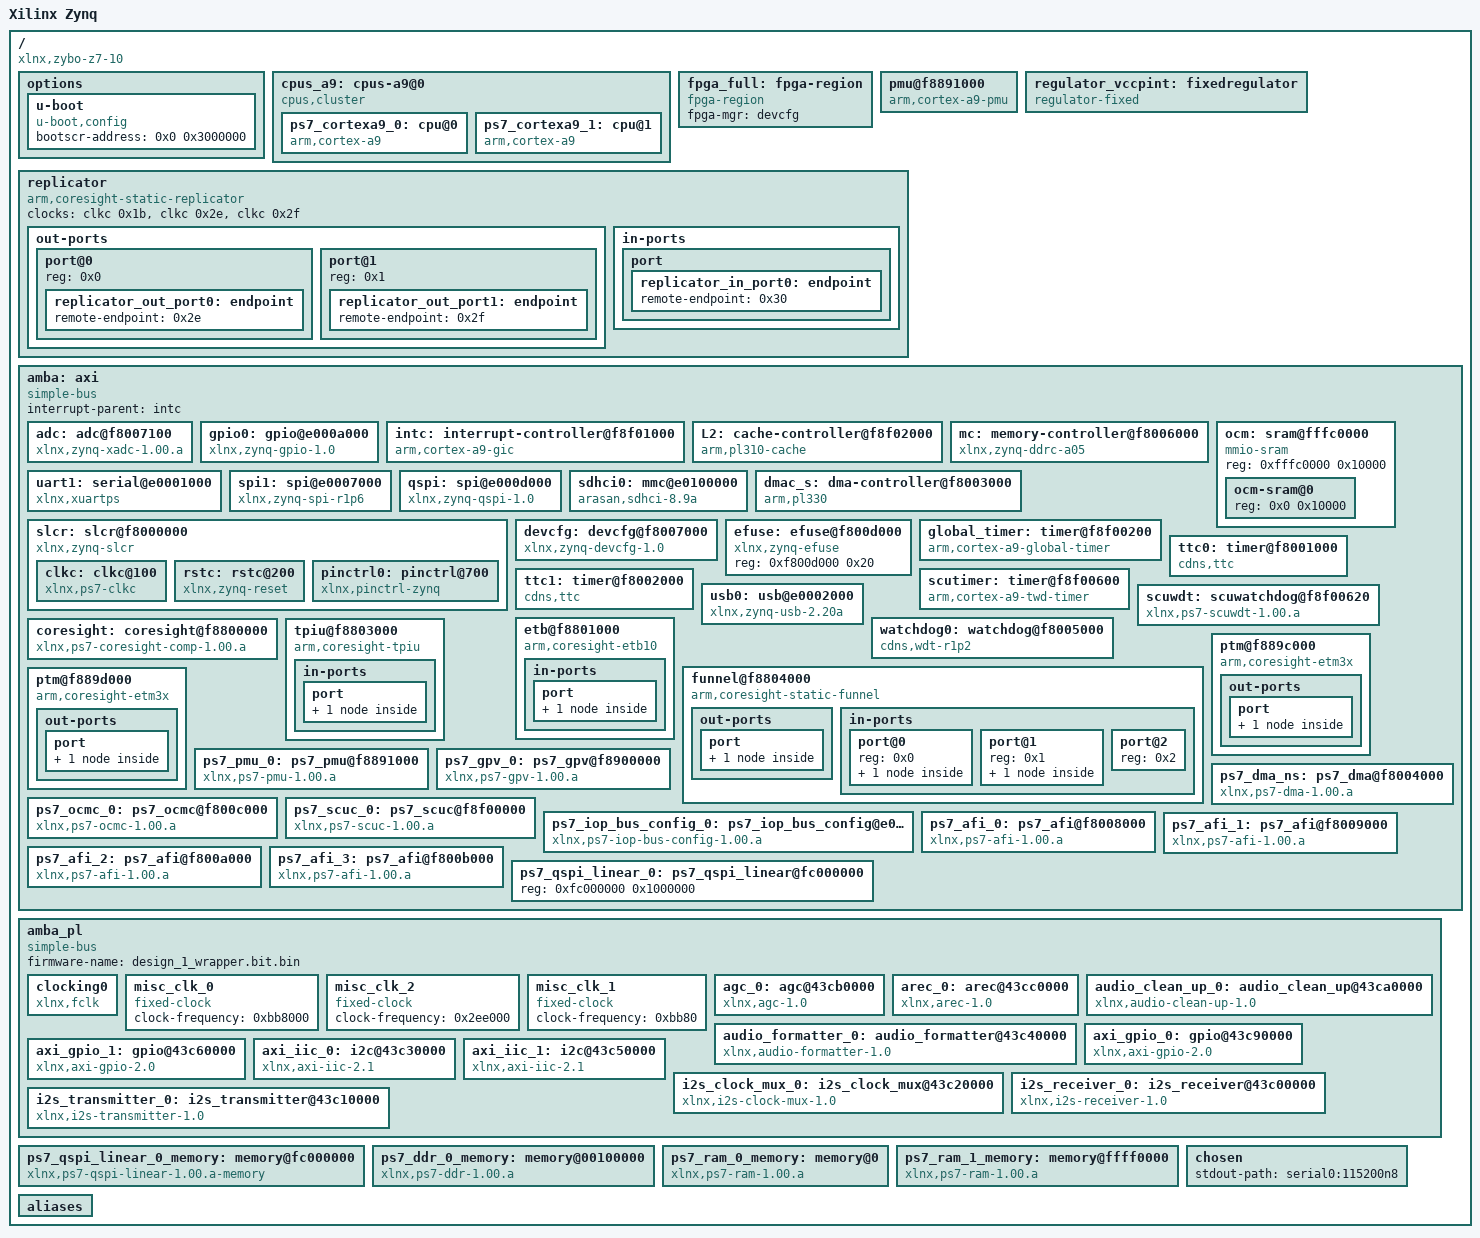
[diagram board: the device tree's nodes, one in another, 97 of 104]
/*
 * Xilinx Zynq 7000 DTSI
 * Describes the hardware common to all Zynq 7000-based boards.
 *
 *  Copyright (C) 2011 - 2015 Xilinx
 * (C) Copyright 2022-2024 Advanced Micro Devices, Inc. All Rights Reserved.
 */

/dts-v1/;

/ {
        #address-cells = <0x1>;
        #size-cells = <0x1>;
        compatible = "xlnx,zybo-z7-10";
        model = "Xilinx Zynq";
        board = "zybo-z7-10";
        device_id = "7z010";
        slrcount = <0x1>;
        family = "Zynq";
        pruned-sdt = <0x1>;

        options {

                u-boot {
                        compatible = "u-boot,config";
                        bootscr-address = <0x0 0x3000000>;
                };
        };

        cpus_a9: cpus-a9@0 {
                #address-cells = <0x1>;
                #size-cells = <0x0>;
                compatible = "cpus,cluster";
                address-map = <0xf0000000 &amba 0xf0000000 0x10000000>,
                 <0x100000 &ps7_ddr_0_memory 0x100000 0x3ff00000>,
                 <0x0 &ps7_ram_0_memory 0x0 0x30000>,
                 <0xffff0000 &ps7_ram_1_memory 0xffff0000 0xfe00>,
                 <0x43c00000 &i2s_receiver_0 0x43c00000 0x10000>,
                 <0x43c10000 &i2s_transmitter_0 0x43c10000 0x10000>,
                 <0x43c20000 &i2s_clock_mux_0 0x43c20000 0x10000>,
                 <0x43c30000 &axi_iic_0 0x43c30000 0x10000>,
                 <0x43c40000 &audio_formatter_0 0x43c40000 0x10000>,
                 <0x43c50000 &axi_iic_1 0x43c50000 0x10000>,
                 <0x43c60000 &axi_gpio_1 0x43c60000 0x10000>,
                 <0x43c90000 &axi_gpio_0 0x43c90000 0x10000>,
                 <0x43ca0000 &audio_clean_up_0 0x43ca0000 0x10000>,
                 <0x43cb0000 &agc_0 0x43cb0000 0x10000>,
                 <0x43cc0000 &arec_0 0x43cc0000 0x10000>,
                 <0xf8008000 &ps7_afi_0 0xf8008000 0x1000>,
                 <0xf8009000 &ps7_afi_1 0xf8009000 0x1000>,
                 <0xf800a000 &ps7_afi_2 0xf800a000 0x1000>,
                 <0xf800b000 &ps7_afi_3 0xf800b000 0x1000>,
                 <0xf8800000 &coresight 0xf8800000 0x100000>,
                 <0xf8006000 &mc 0xf8006000 0x1000>,
                 <0xf8007000 &devcfg 0xf8007000 0x100>,
                 <0xf8004000 &ps7_dma_ns 0xf8004000 0x1000>,
                 <0xf8003000 &dmac_s 0xf8003000 0x1000>,
                 <0xf8f00200 &global_timer 0xf8f00200 0x100>,
                 <0xe000a000 &gpio0 0xe000a000 0x1000>,
                 <0xf8900000 &ps7_gpv_0 0xf8900000 0x100000>,
                 <0xf8f01000 &intc 0xf8f01000 0x1000>,
                 <0xe0200000 &ps7_iop_bus_config_0 0xe0200000 0x1000>,
                 <0xf8f02000 &L2 0xf8f02000 0x1000>,
                 <0xf800c000 &ps7_ocmc_0 0xf800c000 0x1000>,
                 <0xf8891000 &ps7_pmu_0 0xf8891000 0x1000>,
                 <0xe000d000 &qspi 0xe000d000 0x1000>,
                 <0xfc000000 &ps7_qspi_linear_0_memory 0xfc000000 0x1000000>,
                 <0xf8f00000 &ps7_scuc_0 0xf8f00000 0xfd>,
                 <0xf8f00600 &scutimer 0xf8f00600 0x20>,
                 <0xf8f00620 &scuwdt 0xf8f00620 0xe0>,
                 <0xe0100000 &sdhci0 0xe0100000 0x1000>,
                 <0xf8000000 &slcr 0xf8000000 0x1000>,
                 <0xe0007000 &spi1 0xe0007000 0x1000>,
                 <0xe0001000 &uart1 0xe0001000 0x1000>,
                 <0xe0002000 &usb0 0xe0002000 0x1000>,
                 <0xf8007100 &adc 0xf8007100 0x21>;
                #ranges-address-cells = <0x1>;
                #ranges-size-cells = <0x1>;
                phandle = <0x3d>;

                ps7_cortexa9_0: cpu@0 {
                        compatible = "arm,cortex-a9";
                        device_type = "cpu";
                        reg = <0x0>;
                        clocks = <&clkc 0x3>;
                        clock-latency = <0x3e8>;
                        cpu0-supply = <0x2d>;
                        operating-points = <0xa2c2b 0xf4240 0x51616 0xf4240>;
                        xlnx,rable = <0x0>;
                        xlnx,i-cache-size = <0x8000>;
                        xlnx,d-cache-line-size = <0x14>;
                        xlnx,i-cache-line-size = <0x14>;
                        xlnx,cpu-1x-clk-freq-hz = <0x69f6bcb>;
                        xlnx,ip-name = "ps7_cortexa9";
                        xlnx,d-cache-size = <0x8000>;
                        xlnx,num-cores = <0x2>;
                        xlnx,cpu-clk-freq-hz = <0x27bc86bf>;
                        bus-handle = <0x1>;
                        phandle = <0x36>;
                };

                ps7_cortexa9_1: cpu@1 {
                        compatible = "arm,cortex-a9";
                        device_type = "cpu";
                        reg = <0x1>;
                        clocks = <&clkc 0x3>;
                        xlnx,rable = <0x0>;
                        xlnx,i-cache-size = <0x8000>;
                        xlnx,d-cache-line-size = <0x14>;
                        xlnx,i-cache-line-size = <0x14>;
                        xlnx,cpu-1x-clk-freq-hz = <0x69f6bcb>;
                        xlnx,ip-name = "ps7_cortexa9";
                        xlnx,d-cache-size = <0x8000>;
                        xlnx,cpu-clk-freq-hz = <0x27bc86bf>;
                        bus-handle = <0x1>;
                        phandle = <0x38>;
                };
        };

        fpga_full: fpga-region {
                compatible = "fpga-region";
                fpga-mgr = <&devcfg>;
                #address-cells = <0x1>;
                #size-cells = <0x1>;
                ranges;
                phandle = <0x3e>;
        };

        pmu@f8891000 {
                compatible = "arm,cortex-a9-pmu";
                interrupts = <0x0 0x5 0x4 0x0 0x6 0x4>;
                interrupt-parent = <&intc>;
                reg = <0xf8891000 0x1000 0xf8893000 0x1000>;
        };

        regulator_vccpint: fixedregulator {
                compatible = "regulator-fixed";
                regulator-name = "VCCPINT";
                regulator-min-microvolt = <0xf4240>;
                regulator-max-microvolt = <0xf4240>;
                regulator-boot-on;
                regulator-always-on;
                phandle = <0x2d>;
        };

        replicator {
                compatible = "arm,coresight-static-replicator";
                clocks = <&clkc 0x1b>,
                 <&clkc 0x2e>,
                 <&clkc 0x2f>;
                clock-names = "apb_pclk", "dbg_trc", "dbg_apb";

                out-ports {
                        #address-cells = <0x1>;
                        #size-cells = <0x0>;
                        /* replicator output ports */

                        port@0 {
                                reg = <0x0>;

                                replicator_out_port0: endpoint {
                                        remote-endpoint = <0x2e>;
                                        phandle = <0x32>;
                                };
                        };

                        port@1 {
                                reg = <0x1>;

                                replicator_out_port1: endpoint {
                                        remote-endpoint = <0x2f>;
                                        phandle = <0x31>;
                                };
                        };
                };

                in-ports {
                        /* replicator input port */

                        port {

                                replicator_in_port0: endpoint {
                                        remote-endpoint = <0x30>;
                                        phandle = <0x33>;
                                };
                        };
                };
        };

        amba: axi {
                bootph-all;
                compatible = "simple-bus";
                #address-cells = <0x1>;
                #size-cells = <0x1>;
                interrupt-parent = <&intc>;
                ranges;
                phandle = <0x1>;

                adc: adc@f8007100 {
                        compatible = "xlnx,zynq-xadc-1.00.a";
                        reg = <0xf8007100 0x20>;
                        interrupts = <0x0 0x7 0x4>;
                        interrupt-parent = <&intc>;
                        clocks = <&clkc 0xc>;
                        xlnx,rable = <0x0>;
                        status = "okay";
                        xlnx,ip-name = "ps7_xadc";
                        xlnx,name = "ps7_xadc_0";
                        phandle = <0x2b>;
                };

                gpio0: gpio@e000a000 {
                        compatible = "xlnx,zynq-gpio-1.0";
                        #gpio-cells = <0x2>;
                        clocks = <&clkc 0x2a>;
                        gpio-controller;
                        interrupt-controller;
                        #interrupt-cells = <0x2>;
                        interrupt-parent = <&intc>;
                        interrupts = <0x0 0x14 0x4>;
                        reg = <0xe000a000 0x1000>;
                        xlnx,rable = <0x0>;
                        xlnx,mio-gpio-mask = <0x5600>;
                        status = "okay";
                        gpio-mask-high = <0x0>;
                        xlnx,emio-gpio-width = <0x2>;
                        xlnx,ip-name = "ps7_gpio";
                        gpio-mask-low = <0x5600>;
                        emio-gpio-width = <0x2>;
                        xlnx,name = "ps7_gpio_0";
                        phandle = <0x1a>;
                };

                intc: interrupt-controller@f8f01000 {
                        compatible = "arm,cortex-a9-gic";
                        #interrupt-cells = <0x3>;
                        interrupt-controller;
                        reg = <0xf8f01000 0x1000 0xf8f00100 0x100>;
                        xlnx,rable = <0x0>;
                        status = "okay";
                        xlnx,irq-f2p-mode = "DIRECT";
                        xlnx,ip-name = "ps7_intc_dist";
                        xlnx,name = "ps7_intc_dist_0";
                        phandle = <0x1c>;
                };

                L2: cache-controller@f8f02000 {
                        compatible = "arm,pl310-cache";
                        reg = <0xf8f02000 0x1000>;
                        interrupts = <0x0 0x2 0x4>;
                        arm,data-latency = <0x3 0x2 0x2>;
                        arm,tag-latency = <0x2 0x2 0x2>;
                        cache-unified;
                        cache-level = <0x2>;
                        xlnx,rable = <0x0>;
                        status = "okay";
                        xlnx,ip-name = "ps7_pl310";
                        xlnx,name = "ps7_pl310_0";
                        phandle = <0x1e>;
                };

                mc: memory-controller@f8006000 {
                        compatible = "xlnx,zynq-ddrc-a05";
                        reg = <0xf8006000 0x1000>;
                        xlnx,rable = <0x0>;
                        status = "okay";
                        xlnx,ddr-clk-freq-hz = <0x1fca057e>;
                        xlnx,ip-name = "ps7_ddrc";
                        xlnx,has-ecc = <0x0>;
                        xlnx,name = "ps7_ddrc_0";
                        phandle = <0x15>;
                };

                ocm: sram@fffc0000 {
                        compatible = "mmio-sram";
                        reg = <0xfffc0000 0x10000>;
                        #address-cells = <0x1>;
                        #size-cells = <0x1>;
                        ranges = <0x0 0xfffc0000 0x10000>;
                        phandle = <0x43>;

                        ocm-sram@0 {
                                reg = <0x0 0x10000>;
                        };
                };

                uart1: serial@e0001000 {
                        compatible = "xlnx,xuartps", "cdns,uart-r1p8";
                        status = "okay";
                        clocks = <&clkc 0x18>,
                         <&clkc 0x29>;
                        clock-names = "uart_clk", "pclk";
                        reg = <0xe0001000 0x1000>;
                        interrupts = <0x0 0x32 0x4>;
                        interrupt-parent = <&intc>;
                        xlnx,rable = <0x0>;
                        xlnx,clock-freq = <0x5f5e100>;
                        xlnx,has-modem = <0x0>;
                        xlnx,ip-name = "ps7_uart";
                        cts-override;
                        port-number = <0x0>;
                        xlnx,uart-clk-freq-hz = <0x5f5e100>;
                        xlnx,name = "ps7_uart_1";
                        phandle = <0x29>;
                };

                spi1: spi@e0007000 {
                        compatible = "xlnx,zynq-spi-r1p6";
                        reg = <0xe0007000 0x1000>;
                        status = "okay";
                        interrupt-parent = <&intc>;
                        interrupts = <0x0 0x31 0x4>;
                        clocks = <&clkc 0x1a>,
                         <&clkc 0x23>;
                        clock-names = "ref_clk", "pclk";
                        #address-cells = <0x1>;
                        #size-cells = <0x0>;
                        xlnx,rable = <0x0>;
                        xlnx,has-ss0 = <0x1>;
                        xlnx,ip-name = "ps7_spi";
                        xlnx,has-ss1 = <0x1>;
                        num-cs = <0x2>;
                        xlnx,spi-clk-freq-hz = <0x9ef21b0>;
                        xlnx,has-ss2 = <0x0>;
                        xlnx,name = "ps7_spi_1";
                        phandle = <0x28>;
                };

                qspi: spi@e000d000 {
                        compatible = "xlnx,zynq-qspi-1.0";
                        reg = <0xe000d000 0x1000>;
                        interrupt-parent = <&intc>;
                        interrupts = <0x0 0x13 0x4>;
                        clocks = <&clkc 0xa>,
                         <&clkc 0x2b>;
                        clock-names = "ref_clk", "pclk";
                        status = "okay";
                        #address-cells = <0x1>;
                        #size-cells = <0x0>;
                        num-cs = <0x1>;
                        xlnx,qspi-clk-freq-hz = <0xbebc200>;
                        xlnx,rable = <0x0>;
                        xlnx,bus-width = <0x2>;
                        xlnx,ip-name = "ps7_qspi";
                        spi-rx-bus-width = <0x4>;
                        xlnx,connection-mode = <0x0>;
                        spi-tx-bus-width = <0x4>;
                        qspi-fbclk = <0x0>;
                        xlnx,clock-freq = <0xbebc200>;
                        xlnx,fb-clk = <0x1>;
                        xlnx,qspi-mode = <0x0>;
                        xlnx,name = "ps7_qspi_0";
                        xlnx,qspi-bus-width = <0x2>;
                        is-dual = <0x0>;
                        phandle = <0x21>;
                };

                sdhci0: mmc@e0100000 {
                        compatible = "arasan,sdhci-8.9a";
                        status = "okay";
                        clock-names = "clk_xin", "clk_ahb";
                        clocks = <&clkc 0x15>,
                         <&clkc 0x20>;
                        interrupt-parent = <&intc>;
                        interrupts = <0x0 0x18 0x4>;
                        reg = <0xe0100000 0x1000>;
                        xlnx,rable = <0x0>;
                        xlnx,has-power = <0x0>;
                        xlnx,ip-name = "ps7_sdio";
                        xlnx,sdio-clk-freq-hz = <0x2faf080>;
                        xlnx,has-wp = <0x0>;
                        xlnx,has-cd = <0x1>;
                        xlnx,name = "ps7_sd_0";
                        phandle = <0x26>;
                };

                slcr: slcr@f8000000 {
                        bootph-all;
                        #address-cells = <0x1>;
                        #size-cells = <0x1>;
                        compatible = "xlnx,zynq-slcr", "syscon", "simple-mfd";
                        reg = <0xf8000000 0x1000>;
                        ranges;
                        xlnx,rable = <0x0>;
                        status = "okay";
                        xlnx,ip-name = "ps7_slcr";
                        xlnx,name = "ps7_slcr_0";
                        phandle = <0x27>;

                        clkc: clkc@100 {
                                bootph-all;
                                #clock-cells = <0x1>;
                                compatible = "xlnx,ps7-clkc";
                                fclk-enable = <0x1>;
                                clock-output-names = "armpll", "ddrpll", "iopll", "cpu_6or4x", "cpu_3or2x", "cpu_2x", "cpu_1x", "ddr2x", "ddr3x", "dci", "lqspi", "smc", "pcap", "gem0", "gem1", "fclk0", "fclk1", "fclk2", "fclk3", "can0", "can1", "sdio0", "sdio1", "uart0", "uart1", "spi0", "spi1", "dma", "usb0_aper", "usb1_aper", "gem0_aper", "gem1_aper", "sdio0_aper", "sdio1_aper", "spi0_aper", "spi1_aper", "can0_aper", "can1_aper", "i2c0_aper", "i2c1_aper", "uart0_aper", "uart1_aper", "gpio_aper", "lqspi_aper", "smc_aper", "swdt", "dbg_trc", "dbg_apb";
                                reg = <0x100 0x100>;
                                ps-clk-frequency = <0x1fca055>;
                                phandle = <0x2c>;
                        };

                        rstc: rstc@200 {
                                compatible = "xlnx,zynq-reset";
                                reg = <0x200 0x48>;
                                #reset-cells = <0x1>;
                                syscon = <0x27>;
                                phandle = <0x4c>;
                        };

                        pinctrl0: pinctrl@700 {
                                compatible = "xlnx,pinctrl-zynq";
                                reg = <0x700 0x200>;
                                syscon = <0x27>;
                                phandle = <0x4d>;
                        };
                };

                dmac_s: dma-controller@f8003000 {
                        compatible = "arm,pl330", "arm,primecell";
                        reg = <0xf8003000 0x1000>;
                        interrupt-parent = <&intc>;
                        /*
                         * interrupt-names = "abort", "dma0", "dma1", "dma2", "dma3",
                         * "dma4", "dma5", "dma6", "dma7";
                         */
                        interrupts = <0x0 0xd 0x4 0x0 0xe 0x4 0x0 0xf 0x4 0x0 0x10 0x4 0x0 0x11 0x4 0x0 0x28 0x4 0x0 0x29 0x4 0x0 0x2a 0x4 0x0 0x2b 0x4>;
                        #dma-cells = <0x1>;
                        clocks = <&clkc 0x1b>;
                        clock-names = "apb_pclk";
                        xlnx,rable = <0x0>;
                        status = "okay";
                        xlnx,ip-name = "ps7_dma";
                        xlnx,is-secure;
                        xlnx,name = "ps7_dma_s";
                        phandle = <0x18>;
                };

                devcfg: devcfg@f8007000 {
                        compatible = "xlnx,zynq-devcfg-1.0";
                        reg = <0xf8007000 0x100>;
                        interrupt-parent = <&intc>;
                        interrupts = <0x0 0x8 0x4>;
                        clocks = <&clkc 0xc>,
                         <&clkc 0xf>,
                         <&clkc 0x10>,
                         <&clkc 0x11>,
                         <&clkc 0x12>;
                        clock-names = "ref_clk", "fclk0", "fclk1", "fclk2", "fclk3";
                        syscon = <0x27>;
                        xlnx,rable = <0x0>;
                        status = "okay";
                        xlnx,ip-name = "ps7_dev_cfg";
                        xlnx,name = "ps7_dev_cfg_0";
                        phandle = <0x16>;
                };

                efuse: efuse@f800d000 {
                        compatible = "xlnx,zynq-efuse";
                        reg = <0xf800d000 0x20>;
                        phandle = <0x4e>;
                };

                global_timer: timer@f8f00200 {
                        compatible = "arm,cortex-a9-global-timer";
                        reg = <0xf8f00200 0x20>;
                        interrupts = <0x1 0xb 0x301>;
                        interrupt-parent = <&intc>;
                        clocks = <&clkc 0x4>;
                        xlnx,rable = <0x0>;
                        status = "okay";
                        xlnx,ip-name = "ps7_globaltimer";
                        xlnx,name = "ps7_globaltimer_0";
                        phandle = <0x19>;
                };

                ttc0: timer@f8001000 {
                        interrupt-parent = <&intc>;
                        interrupts = <0x0 0xa 0x4 0x0 0xb 0x4 0x0 0xc 0x4>;
                        compatible = "cdns,ttc";
                        clocks = <&clkc 0x6>;
                        reg = <0xf8001000 0x1000>;
                        phandle = <0x4f>;
                };

                ttc1: timer@f8002000 {
                        interrupt-parent = <&intc>;
                        interrupts = <0x0 0x25 0x4 0x0 0x26 0x4 0x0 0x27 0x4>;
                        compatible = "cdns,ttc";
                        clocks = <&clkc 0x6>;
                        reg = <0xf8002000 0x1000>;
                        phandle = <0x50>;
                };

                scutimer: timer@f8f00600 {
                        bootph-all;
                        interrupt-parent = <&intc>;
                        interrupts = <0x1 0xd 0x301>;
                        compatible = "arm,cortex-a9-twd-timer";
                        reg = <0xf8f00600 0x20>;
                        clocks = <&clkc 0x4>;
                        xlnx,rable = <0x0>;
                        status = "okay";
                        xlnx,ip-name = "ps7_scutimer";
                        xlnx,name = "ps7_scutimer_0";
                        phandle = <0x24>;
                };

                scuwdt: scuwatchdog@f8f00620 {
                        interrupt-parent = <&intc>;
                        interrupts = <0x1 0xe 0x4>;
                        compatible = "xlnx,ps7-scuwdt-1.00.a";
                        reg = <0xf8f00620 0xe0>;
                        xlnx,rable = <0x0>;
                        status = "okay";
                        xlnx,ip-name = "ps7_scuwdt";
                        xlnx,name = "ps7_scuwdt_0";
                        phandle = <0x25>;
                };

                usb0: usb@e0002000 {
                        compatible = "xlnx,zynq-usb-2.20a", "chipidea,usb2";
                        status = "okay";
                        clocks = <&clkc 0x1c>;
                        interrupt-parent = <&intc>;
                        interrupts = <0x0 0x15 0x4>;
                        reg = <0xe0002000 0x1000>;
                        phy_type = "ulpi";
                        xlnx,rable = <0x0>;
                        xlnx,usb-reset = "MIO , 46";
                        xlnx,ip-name = "ps7_usb";
                        usb-reset = <0x1a 0x2e 0x0>;
                        xlnx,name = "ps7_usb_0";
                        phandle = <0x2a>;
                };

                watchdog0: watchdog@f8005000 {
                        clocks = <&clkc 0x2d>;
                        compatible = "cdns,wdt-r1p2";
                        interrupt-parent = <&intc>;
                        interrupts = <0x0 0x9 0x1>;
                        reg = <0xf8005000 0x1000>;
                        timeout-sec = <0xa>;
                        phandle = <0x52>;
                };

                coresight: coresight@f8800000 {
                        compatible = "xlnx,ps7-coresight-comp-1.00.a";
                        status = "okay";
                        reg = <0xf8800000 0x100000>;
                        xlnx,rable = <0x0>;
                        xlnx,ip-name = "ps7_coresight_comp";
                        xlnx,name = "ps7_coresight_comp_0";
                        phandle = <0x14>;
                };

                etb@f8801000 {
                        compatible = "arm,coresight-etb10", "arm,primecell";
                        reg = <0xf8801000 0x1000>;
                        clocks = <&clkc 0x1b>,
                         <&clkc 0x2e>,
                         <&clkc 0x2f>;
                        clock-names = "apb_pclk", "dbg_trc", "dbg_apb";

                        in-ports {

                                port {

                                        etb_in_port: endpoint {
                                                remote-endpoint = <0x31>;
                                                phandle = <0x2f>;
                                        };
                                };
                        };
                };

                tpiu@f8803000 {
                        compatible = "arm,coresight-tpiu", "arm,primecell";
                        reg = <0xf8803000 0x1000>;
                        clocks = <&clkc 0x1b>,
                         <&clkc 0x2e>,
                         <&clkc 0x2f>;
                        clock-names = "apb_pclk", "dbg_trc", "dbg_apb";

                        in-ports {

                                port {

                                        tpiu_in_port: endpoint {
                                                remote-endpoint = <0x32>;
                                                phandle = <0x2e>;
                                        };
                                };
                        };
                };

                funnel@f8804000 {
                        compatible = "arm,coresight-static-funnel", "arm,primecell";
                        reg = <0xf8804000 0x1000>;
                        clocks = <&clkc 0x1b>,
                         <&clkc 0x2e>,
                         <&clkc 0x2f>;
                        clock-names = "apb_pclk", "dbg_trc", "dbg_apb";
                        /* funnel output ports */

                        out-ports {

                                port {

                                        funnel_out_port: endpoint {
                                                remote-endpoint = <0x33>;
                                                phandle = <0x30>;
                                        };
                                };
                        };

                        in-ports {
                                #address-cells = <0x1>;
                                #size-cells = <0x0>;
                                /* funnel input ports */

                                port@0 {
                                        reg = <0x0>;

                                        funnel0_in_port0: endpoint {
                                                remote-endpoint = <0x34>;
                                                phandle = <0x37>;
                                        };
                                };

                                port@1 {
                                        reg = <0x1>;

                                        funnel0_in_port1: endpoint {
                                                remote-endpoint = <0x35>;
                                                phandle = <0x39>;
                                        };
                                };

                                port@2 {
                                        reg = <0x2>;
                                };
                        };
                };

                ptm@f889c000 {
                        compatible = "arm,coresight-etm3x", "arm,primecell";
                        reg = <0xf889c000 0x1000>;
                        clocks = <&clkc 0x1b>,
                         <&clkc 0x2e>,
                         <&clkc 0x2f>;
                        clock-names = "apb_pclk", "dbg_trc", "dbg_apb";
                        cpu = <0x36>;

                        out-ports {

                                port {

                                        ptm0_out_port: endpoint {
                                                remote-endpoint = <0x37>;
                                                phandle = <0x34>;
                                        };
                                };
                        };
                };

                ptm@f889d000 {
                        compatible = "arm,coresight-etm3x", "arm,primecell";
                        reg = <0xf889d000 0x1000>;
                        clocks = <&clkc 0x1b>,
                         <&clkc 0x2e>,
                         <&clkc 0x2f>;
                        clock-names = "apb_pclk", "dbg_trc", "dbg_apb";
                        cpu = <0x38>;

                        out-ports {

                                port {

                                        ptm1_out_port: endpoint {
                                                remote-endpoint = <0x39>;
                                                phandle = <0x35>;
                                        };
                                };
                        };
                };

                ps7_pmu_0: ps7_pmu@f8891000 {
                        xlnx,rable = <0x0>;
                        compatible = "xlnx,ps7-pmu-1.00.a";
                        status = "okay";
                        xlnx,ip-name = "ps7_pmu";
                        reg = <0xf8891000 0x1000 0xf8893000 0x1000>;
                        xlnx,name = "ps7_pmu_0";
                        phandle = <0x20>;
                };

                ps7_ocmc_0: ps7_ocmc@f800c000 {
                        xlnx,rable = <0x0>;
                        compatible = "xlnx,ps7-ocmc-1.00.a";
                        status = "okay";
                        xlnx,ip-name = "ps7_ocmc";
                        reg = <0xf800c000 0x1000>;
                        xlnx,name = "ps7_ocmc_0";
                        phandle = <0x1f>;
                };

                ps7_gpv_0: ps7_gpv@f8900000 {
                        xlnx,rable = <0x0>;
                        compatible = "xlnx,ps7-gpv-1.00.a";
                        status = "okay";
                        xlnx,ip-name = "ps7_gpv";
                        reg = <0xf8900000 0x100000>;
                        xlnx,name = "ps7_gpv_0";
                        phandle = <0x1b>;
                };

                ps7_scuc_0: ps7_scuc@f8f00000 {
                        xlnx,rable = <0x0>;
                        compatible = "xlnx,ps7-scuc-1.00.a";
                        status = "okay";
                        xlnx,ip-name = "ps7_scuc";
                        reg = <0xf8f00000 0xfd>;
                        xlnx,name = "ps7_scuc_0";
                        phandle = <0x23>;
                };

                ps7_iop_bus_config_0: ps7_iop_bus_config@e0200000 {
                        xlnx,rable = <0x0>;
                        compatible = "xlnx,ps7-iop-bus-config-1.00.a";
                        status = "okay";
                        xlnx,ip-name = "ps7_iop_bus_config";
                        reg = <0xe0200000 0x1000>;
                        xlnx,name = "ps7_iop_bus_config_0";
                        phandle = <0x1d>;
                };

                ps7_dma_ns: ps7_dma@f8004000 {
                        xlnx,rable = <0x0>;
                        compatible = "xlnx,ps7-dma-1.00.a";
                        status = "okay";
                        xlnx,ip-name = "ps7_dma";
                        xlnx,is-secure;
                        reg = <0xf8004000 0x1000>;
                        xlnx,name = "ps7_dma_ns";
                        phandle = <0x17>;
                };

                ps7_afi_0: ps7_afi@f8008000 {
                        xlnx,rable = <0x0>;
                        compatible = "xlnx,ps7-afi-1.00.a";
                        status = "okay";
                        xlnx,ip-name = "ps7_afi";
                        reg = <0xf8008000 0x1000>;
                        xlnx,name = "ps7_afi_0";
                        phandle = <0x10>;
                };

                ps7_afi_1: ps7_afi@f8009000 {
                        xlnx,rable = <0x0>;
                        compatible = "xlnx,ps7-afi-1.00.a";
                        status = "okay";
                        xlnx,ip-name = "ps7_afi";
                        reg = <0xf8009000 0x1000>;
                        xlnx,name = "ps7_afi_1";
                        phandle = <0x11>;
                };

                ps7_afi_2: ps7_afi@f800a000 {
                        xlnx,rable = <0x0>;
                        compatible = "xlnx,ps7-afi-1.00.a";
                        status = "okay";
                        xlnx,ip-name = "ps7_afi";
                        reg = <0xf800a000 0x1000>;
                        xlnx,name = "ps7_afi_2";
                        phandle = <0x12>;
                };

                ps7_afi_3: ps7_afi@f800b000 {
                        xlnx,rable = <0x0>;
                        compatible = "xlnx,ps7-afi-1.00.a";
                        status = "okay";
                        xlnx,ip-name = "ps7_afi";
                        reg = <0xf800b000 0x1000>;
                        xlnx,name = "ps7_afi_3";
                        phandle = <0x13>;
                };

                ps7_qspi_linear_0: ps7_qspi_linear@fc000000 {
                        reg = <0xfc000000 0x1000000>;
                        phandle = <0x58>;
                };
        };

        amba_pl: amba_pl {
                ranges;
                compatible = "simple-bus";
                #address-cells = <0x1>;
                #size-cells = <0x1>;
                firmware-name = "design_1_wrapper.bit.bin";
                phandle = <0x59>;

                clocking0: clocking0 {
                        compatible = "xlnx,fclk";
                        assigned-clocks = <&clkc 0xf>;
                        assigned-clock-rates = <0x5f5e100>;
                        #clock-cells = <0x0>;
                        clock-output-names = "fabric_clk";
                        clocks = <&clkc 0xf>;
                        phandle = <0x5a>;
                };

                misc_clk_0: misc_clk_0 {
                        compatible = "fixed-clock";
                        clock-frequency = <0xbb8000>;
                        #clock-cells = <0x0>;
                        phandle = <0x3a>;
                };

                misc_clk_2: misc_clk_2 {
                        compatible = "fixed-clock";
                        clock-frequency = <0x2ee000>;
                        #clock-cells = <0x0>;
                        phandle = <0x3c>;
                };

                misc_clk_1: misc_clk_1 {
                        compatible = "fixed-clock";
                        clock-frequency = <0xbb80>;
                        #clock-cells = <0x0>;
                        phandle = <0x3b>;
                };

                agc_0: agc@43cb0000 {
                        xlnx,rable = <0x0>;
                        xlnx,s00-axi-data-width = <0x20>;
                        compatible = "xlnx,agc-1.0";
                        status = "okay";
                        clock-names = "s00_axi_aclk";
                        xlnx,s00-axi-addr-width = <0x6>;
                        xlnx,ip-name = "agc";
                        xlnx,edk-iptype = "PERIPHERAL";
                        reg = <0x43cb0000 0x10000>;
                        clocks = <&clkc 0xf>;
                        xlnx,name = "agc_0";
                        phandle = <0xe>;
                };

                arec_0: arec@43cc0000 {
                        compatible = "xlnx,arec-1.0";
                        interrupts = <0x0 0x34 0x4>;
                        xlnx,s00-axi-data-width = <0x20>;
                        xlnx,rable = <0x0>;
                        interrupt-parent = <&intc>;
                        xlnx,ip-name = "arec";
                        reg = <0x43cc0000 0x10000>;
                        clocks = <&clkc 0xf>;
                        xlnx,edk-iptype = "PERIPHERAL";
                        status = "okay";
                        clock-names = "s00_axi_aclk";
                        xlnx,s00-axi-addr-width = <0x6>;
                        interrupt-names = "irq";
                        xlnx,name = "arec_0";
                        phandle = <0xf>;
                };

                audio_clean_up_0: audio_clean_up@43ca0000 {
                        compatible = "xlnx,audio-clean-up-1.0";
                        xlnx,ii = "52 , ~ , 74";
                        xlnx,machine = <0x40>;
                        xlnx,s-axi-acu-addr-width = <0x7>;
                        xlnx,rable = <0x0>;
                        xlnx,ip-name = "audio_clean_up";
                        reg = <0x43ca0000 0x10000>;
                        clocks = <&clkc 0xf>;
                        xlnx,clk-period = <0xa>;
                        xlnx,s-axi-acu-data-width = <0x20>;
                        xlnx,edk-iptype = "PERIPHERAL";
                        status = "okay";
                        clock-names = "ap_clk";
                        xlnx,combinational = <0x0>;
                        xlnx,latency = <0x33>;
                        xlnx,name = "audio_clean_up_0";
                        phandle = <0xd>;
                };

                audio_formatter_0: audio_formatter@43c40000 {
                        xlnx,rx = <0xd>;
                        interrupts = <0x0 0x1f 0x4 0x0 0x20 0x4>;
                        compatible = "xlnx,audio-formatter-1.0", "xlnx,audio-formatter-1.0";
                        xlnx,packing-mode-mm2s = <0x0>;
                        xlnx,mm2s-async-clock = <0x0>;
                        xlnx,tx = <0xe>;
                        xlnx,mm2s-addr-width = <0x20>;
                        interrupt-parent = <&intc>;
                        xlnx,rable = <0x0>;
                        xlnx,s2mm-dataformat = <0x1>;
                        xlnx,ip-name = "audio_formatter";
                        reg = <0x43c40000 0x10000>;
                        xlnx,include-s2mm = <0x1>;
                        xlnx,max-num-channels-mm2s = <0x2>;
                        clocks = <&misc_clk_0>,
                         <&clkc 0xf>,
                         <&clkc 0xf>,
                         <&clkc 0xf>;
                        xlnx,s2mm-async-clock = <0x0>;
                        xlnx,packing-mode-s2mm = <0x0>;
                        xlnx,edk-iptype = "PERIPHERAL";
                        xlnx,s2mm-addr-width = <0x20>;
                        status = "okay";
                        clock-names = "aud_mclk", "m_axis_mm2s_aclk", "s_axi_lite_aclk", "s_axis_s2mm_aclk";
                        xlnx,mm2s-dataformat = <0x3>;
                        interrupt-names = "irq_mm2s", "irq_s2mm";
                        xlnx,include-mm2s = <0x1>;
                        xlnx,max-num-channels-s2mm = <0x2>;
                        xlnx,name = "audio_formatter_0";
                        phandle = <0x9>;
                };

                axi_gpio_0: gpio@43c90000 {
                        #interrupt-cells = <0x2>;
                        interrupts = <0x0 0x22 0x4>;
                        xlnx,gpio-board-interface = "btns_4bits";
                        compatible = "xlnx,axi-gpio-2.0", "xlnx,xps-gpio-1.00.a";
                        xlnx,all-outputs = <0x0>;
                        #gpio-cells = <0x2>;
                        xlnx,gpio-width = <0x4>;
                        interrupt-parent = <&intc>;
                        xlnx,rable = <0x0>;
                        xlnx,dout-default = <0x0>;
                        xlnx,is-dual = <0x1>;
                        xlnx,ip-name = "axi_gpio";
                        xlnx,tri-default-2 = <0xffffffff>;
                        reg = <0x43c90000 0x10000>;
                        xlnx,all-inputs-2 = <0x0>;
                        clocks = <&clkc 0xf>;
                        xlnx,all-outputs-2 = <0x1>;
                        gpio-controller;
                        xlnx,interrupt-present = <0x1>;
                        xlnx,gpio2-board-interface = "leds_4bits";
                        xlnx,edk-iptype = "PERIPHERAL";
                        xlnx,dout-default-2 = <0x0>;
                        status = "okay";
                        xlnx,gpio2-width = <0x4>;
                        clock-names = "s_axi_aclk";
                        xlnx,use-board-flow;
                        interrupt-controller;
                        interrupt-names = "ip2intc_irpt";
                        xlnx,tri-default = <0xffffffff>;
                        xlnx,name = "axi_gpio_0";
                        xlnx,all-inputs = <0x1>;
                        phandle = <0xc>;
                };

                axi_gpio_1: gpio@43c60000 {
                        #interrupt-cells = <0x2>;
                        interrupts = <0x0 0x24 0x4>;
                        xlnx,gpio-board-interface = "Custom";
                        compatible = "xlnx,axi-gpio-2.0", "xlnx,xps-gpio-1.00.a";
                        xlnx,all-outputs = <0x0>;
                        #gpio-cells = <0x2>;
                        xlnx,gpio-width = <0x2>;
                        interrupt-parent = <&intc>;
                        xlnx,rable = <0x0>;
                        xlnx,dout-default = <0x0>;
                        xlnx,is-dual = <0x1>;
                        xlnx,ip-name = "axi_gpio";
                        xlnx,tri-default-2 = <0xffffffff>;
                        reg = <0x43c60000 0x10000>;
                        xlnx,all-inputs-2 = <0x0>;
                        clocks = <&clkc 0xf>;
                        xlnx,all-outputs-2 = <0x1>;
                        gpio-controller;
                        xlnx,interrupt-present = <0x1>;
                        xlnx,gpio2-board-interface = "Custom";
                        xlnx,edk-iptype = "PERIPHERAL";
                        xlnx,dout-default-2 = <0x0>;
                        status = "okay";
                        xlnx,gpio2-width = <0x2>;
                        clock-names = "s_axi_aclk";
                        interrupt-controller;
                        interrupt-names = "ip2intc_irpt";
                        xlnx,tri-default = <0xffffffff>;
                        xlnx,name = "axi_gpio_1";
                        xlnx,all-inputs = <0x1>;
                        phandle = <0xb>;
                };

                axi_iic_0: i2c@43c30000 {
                        interrupts = <0x0 0x21 0x4>;
                        xlnx,iic-freq-khz = <0x64>;
                        compatible = "xlnx,axi-iic-2.1", "xlnx,xps-iic-2.00.a";
                        xlnx,scl-inertial-delay = <0x0>;
                        interrupt-parent = <&intc>;
                        xlnx,rable = <0x0>;
                        xlnx,ip-name = "axi_iic";
                        xlnx,disable-setup-violation-check = <0x0>;
                        reg = <0x43c30000 0x10000>;
                        clocks = <&clkc 0xf>;
                        xlnx,gpo-width = <0x1>;
                        xlnx,edk-iptype = "PERIPHERAL";
                        xlnx,static-timing-reg-width = <0x0>;
                        xlnx,sda-level = <0x1>;
                        status = "okay";
                        clock-names = "s_axi_aclk";
                        xlnx,ten-bit-adr = <0x0>;
                        xlnx,default-value = <0x0>;
                        interrupt-names = "iic2intc_irpt";
                        xlnx,iic-board-interface = "Custom";
                        xlnx,timing-reg-width = <0x20>;
                        xlnx,iic-freq = <0x186a0>;
                        xlnx,smbus-pmbus-host = <0x0>;
                        xlnx,name = "axi_iic_0";
                        xlnx,axi-aclk-freq-mhz = <0x64>;
                        xlnx,sda-inertial-delay = <0x0>;
                        phandle = <0x8>;
                };

                axi_iic_1: i2c@43c50000 {
                        interrupts = <0x0 0x23 0x4>;
                        xlnx,iic-freq-khz = <0x64>;
                        compatible = "xlnx,axi-iic-2.1", "xlnx,xps-iic-2.00.a";
                        xlnx,scl-inertial-delay = <0x0>;
                        interrupt-parent = <&intc>;
                        xlnx,rable = <0x0>;
                        xlnx,ip-name = "axi_iic";
                        xlnx,disable-setup-violation-check = <0x0>;
                        reg = <0x43c50000 0x10000>;
                        clocks = <&clkc 0xf>;
                        xlnx,gpo-width = <0x1>;
                        xlnx,edk-iptype = "PERIPHERAL";
                        xlnx,static-timing-reg-width = <0x0>;
                        xlnx,sda-level = <0x1>;
                        status = "okay";
                        clock-names = "s_axi_aclk";
                        xlnx,ten-bit-adr = <0x0>;
                        xlnx,default-value = <0x0>;
                        interrupt-names = "iic2intc_irpt";
                        xlnx,iic-board-interface = "Custom";
                        xlnx,timing-reg-width = <0x20>;
                        xlnx,iic-freq = <0x186a0>;
                        xlnx,smbus-pmbus-host = <0x0>;
                        xlnx,name = "axi_iic_1";
                        xlnx,axi-aclk-freq-mhz = <0x64>;
                        xlnx,sda-inertial-delay = <0x0>;
                        phandle = <0xa>;
                };

                i2s_clock_mux_0: i2s_clock_mux@43c20000 {
                        xlnx,rable = <0x0>;
                        xlnx,s00-axi-data-width = <0x20>;
                        compatible = "xlnx,i2s-clock-mux-1.0";
                        status = "okay";
                        clock-names = "lrclk_rx", "lrclk_tx", "s00_axi_aclk", "sclk_rx", "sclk_tx";
                        xlnx,s00-axi-addr-width = <0x4>;
                        xlnx,ip-name = "i2s_clock_mux";
                        xlnx,edk-iptype = "PERIPHERAL";
                        reg = <0x43c20000 0x10000>;
                        clocks = <&misc_clk_1>,
                         <&misc_clk_1>,
                         <&clkc 0xf>,
                         <&misc_clk_2>,
                         <&misc_clk_2>;
                        xlnx,name = "i2s_clock_mux_0";
                        phandle = <0x7>;
                };

                i2s_receiver_0: i2s_receiver@43c00000 {
                        aud_mclk = <0xbb8000>;
                        interrupts = <0x0 0x1d 0x4>;
                        compatible = "xlnx,i2s-receiver-1.0", "xlnx,i2s-receiver-1.0";
                        xlnx,dwidth = <0x10>;
                        xlnx,depth = <0x400>;
                        interrupt-parent = <&intc>;
                        xlnx,rable = <0x0>;
                        xlnx,ip-name = "i2s_receiver";
                        reg = <0x43c00000 0x10000>;
                        clocks = <&misc_clk_0>,
                         <&clkc 0xf>,
                         <&clkc 0xf>;
                        xlnx,num-channels = <0x1>;
                        xlnx,i2srx-board-interface = "Custom";
                        xlnx,edk-iptype = "PERIPHERAL";
                        xlnx,is-master = <0x1>;
                        status = "okay";
                        clock-names = "aud_mclk", "m_axis_aud_aclk", "s_axi_ctrl_aclk";
                        xlnx,32bit-lr = <0x0>;
                        interrupt-names = "irq";
                        xlnx,name = "i2s_receiver_0";
                        phandle = <0x5>;
                };

                i2s_transmitter_0: i2s_transmitter@43c10000 {
                        aud_mclk = <0xbb8000>;
                        interrupts = <0x0 0x1e 0x4>;
                        compatible = "xlnx,i2s-transmitter-1.0", "xlnx,i2s-transmitter-1.0";
                        xlnx,dwidth = <0x10>;
                        xlnx,depth = <0x80>;
                        interrupt-parent = <&intc>;
                        xlnx,rable = <0x0>;
                        xlnx,ip-name = "i2s_transmitter";
                        reg = <0x43c10000 0x10000>;
                        clocks = <&misc_clk_0>,
                         <&clkc 0xf>,
                         <&clkc 0xf>;
                        xlnx,num-channels = <0x1>;
                        xlnx,edk-iptype = "PERIPHERAL";
                        xlnx,is-master = <0x1>;
                        xlnx,i2stx-board-interface = "Custom";
                        status = "okay";
                        clock-names = "aud_mclk", "s_axi_ctrl_aclk", "s_axis_aud_aclk";
                        xlnx,32bit-lr = <0x0>;
                        interrupt-names = "irq";
                        xlnx,name = "i2s_transmitter_0";
                        phandle = <0x6>;
                };
        };

        ps7_qspi_linear_0_memory: memory@fc000000 {
                compatible = "xlnx,ps7-qspi-linear-1.00.a-memory";
                xlnx,ip-name = "ps7_qspi_linear";
                device_type = "memory";
                memory_type = "linear_flash";
                reg = <0xfc000000 0x1000000>;
                phandle = <0x22>;
        };

        ps7_ddr_0_memory: memory@00100000 {
                compatible = "xlnx,ps7-ddr-1.00.a";
                xlnx,ip-name = "ps7_ddr";
                device_type = "memory";
                memory_type = "memory";
                reg = <0x100000 0x3ff00000>;
                phandle = <0x2>;
        };

        ps7_ram_0_memory: memory@0 {
                compatible = "xlnx,ps7-ram-1.00.a";
                xlnx,ip-name = "ps7_ram";
                device_type = "memory";
                memory_type = "memory";
                reg = <0x0 0x30000>;
                phandle = <0x3>;
        };

        ps7_ram_1_memory: memory@ffff0000 {
                compatible = "xlnx,ps7-ram-1.00.a";
                xlnx,ip-name = "ps7_ram";
                device_type = "memory";
                memory_type = "memory";
                reg = <0xffff0000 0xfe00>;
                phandle = <0x4>;
        };

        chosen {
                stdout-path = "serial0:115200n8";
        };

        aliases {
                serial0 = "/axi/serial@e0001000";
                spi0 = "/axi/spi@e000d000";
                serial1 = "/axi/coresight@f8800000";
                i2c0 = "/amba_pl/i2c@43c30000";
                i2c1 = "/amba_pl/i2c@43c50000";
        };

        __symbols__ {
                cpus_a9 = "/cpus-a9@0";
                ps7_cortexa9_0 = "/cpus-a9@0/cpu@0";
                ps7_cortexa9_1 = "/cpus-a9@0/cpu@1";
                fpga_full = "/fpga-region";
                regulator_vccpint = "/fixedregulator";
                replicator_out_port0 = "/replicator/out-ports/port@0/endpoint";
                replicator_out_port1 = "/replicator/out-ports/port@1/endpoint";
                replicator_in_port0 = "/replicator/in-ports/port/endpoint";
                amba = "/axi";
                adc = "/axi/adc@f8007100";
                gpio0 = "/axi/gpio@e000a000";
                intc = "/axi/interrupt-controller@f8f01000";
                L2 = "/axi/cache-controller@f8f02000";
                mc = "/axi/memory-controller@f8006000";
                ocm = "/axi/sram@fffc0000";
                uart1 = "/axi/serial@e0001000";
                spi1 = "/axi/spi@e0007000";
                qspi = "/axi/spi@e000d000";
                sdhci0 = "/axi/mmc@e0100000";
                slcr = "/axi/slcr@f8000000";
                clkc = "/axi/slcr@f8000000/clkc@100";
                rstc = "/axi/slcr@f8000000/rstc@200";
                pinctrl0 = "/axi/slcr@f8000000/pinctrl@700";
                dmac_s = "/axi/dma-controller@f8003000";
                devcfg = "/axi/devcfg@f8007000";
                efuse = "/axi/efuse@f800d000";
                global_timer = "/axi/timer@f8f00200";
                ttc0 = "/axi/timer@f8001000";
                ttc1 = "/axi/timer@f8002000";
                scutimer = "/axi/timer@f8f00600";
                scuwdt = "/axi/scuwatchdog@f8f00620";
                usb0 = "/axi/usb@e0002000";
                watchdog0 = "/axi/watchdog@f8005000";
                coresight = "/axi/coresight@f8800000";
                etb_in_port = "/axi/etb@f8801000/in-ports/port/endpoint";
                tpiu_in_port = "/axi/tpiu@f8803000/in-ports/port/endpoint";
                funnel_out_port = "/axi/funnel@f8804000/out-ports/port/endpoint";
                funnel0_in_port0 = "/axi/funnel@f8804000/in-ports/port@0/endpoint";
                funnel0_in_port1 = "/axi/funnel@f8804000/in-ports/port@1/endpoint";
                ptm0_out_port = "/axi/ptm@f889c000/out-ports/port/endpoint";
                ptm1_out_port = "/axi/ptm@f889d000/out-ports/port/endpoint";
                ps7_pmu_0 = "/axi/ps7_pmu@f8891000";
                ps7_ocmc_0 = "/axi/ps7_ocmc@f800c000";
                ps7_gpv_0 = "/axi/ps7_gpv@f8900000";
                ps7_scuc_0 = "/axi/ps7_scuc@f8f00000";
                ps7_iop_bus_config_0 = "/axi/ps7_iop_bus_config@e0200000";
                ps7_dma_ns = "/axi/ps7_dma@f8004000";
                ps7_afi_0 = "/axi/ps7_afi@f8008000";
                ps7_afi_1 = "/axi/ps7_afi@f8009000";
                ps7_afi_2 = "/axi/ps7_afi@f800a000";
                ps7_afi_3 = "/axi/ps7_afi@f800b000";
                ps7_qspi_linear_0 = "/axi/ps7_qspi_linear@fc000000";
                amba_pl = "/amba_pl";
                clocking0 = "/amba_pl/clocking0";
                misc_clk_0 = "/amba_pl/misc_clk_0";
                misc_clk_2 = "/amba_pl/misc_clk_2";
                misc_clk_1 = "/amba_pl/misc_clk_1";
                agc_0 = "/amba_pl/agc@43cb0000";
                arec_0 = "/amba_pl/arec@43cc0000";
                audio_clean_up_0 = "/amba_pl/audio_clean_up@43ca0000";
                audio_formatter_0 = "/amba_pl/audio_formatter@43c40000";
                axi_gpio_0 = "/amba_pl/gpio@43c90000";
                axi_gpio_1 = "/amba_pl/gpio@43c60000";
                axi_iic_0 = "/amba_pl/i2c@43c30000";
                axi_iic_1 = "/amba_pl/i2c@43c50000";
                i2s_clock_mux_0 = "/amba_pl/i2s_clock_mux@43c20000";
                i2s_receiver_0 = "/amba_pl/i2s_receiver@43c00000";
                i2s_transmitter_0 = "/amba_pl/i2s_transmitter@43c10000";
                ps7_qspi_linear_0_memory = "/memory@fc000000";
                ps7_ddr_0_memory = "/memory@00100000";
                ps7_ram_0_memory = "/memory@0";
                ps7_ram_1_memory = "/memory@ffff0000";
        };
};
